# PIC32MZ2051W104132 device description
Architecture: MIPS; Family: PIC32MZW; Series: PIC32MZW
Registers are 32-bit, read-write, no defined reset value unless marked. A register's access mark holds for its fields unless they carry their own. Offsets are from the block's base; [hi:lo] are bit positions; {n}, {i} and the like mark numbered series; 'fields as' and 'values as' point back to an identical list.

## ADCHS
Instances: ADCHS0 0x1f821000 in periph_pb2
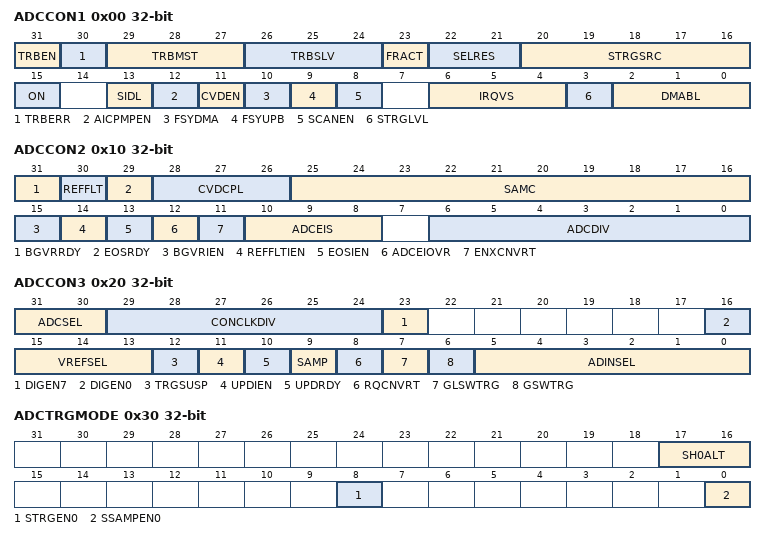
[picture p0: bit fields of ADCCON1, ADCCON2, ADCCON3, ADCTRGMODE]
0x00 ADCCON1 — ADC Control Register 1
  [31] TRBEN — Turbo Channel Enable bit
    1=Enable the Turbo channel; 0=Disable the Turbo channel
  [30] TRBERR — Turbo Channel Error Status bit
    1=An error occurred while setting the Turbo channel and Turbo channel function to be disabled regardless of the TRBEN bit being set to 1; 0=Turbo channel error did not occur
  [29:27] TRBMST — Turbo Master ADCx bits
    {v}=ADC{v} is selected as the Turbo Master (v=0..4)
  [26:24] TRBSLV — Turbo Slave ADCx bits
    {v}=ADC{v} is selected as the Turbo Slave (v=0..4)
  [23] FRACT — Fractional Data Output Format bit
    1=Fractional; 0=Integer
  [22:21] SELRES — Shared ADC Resolution bits
    3=12 bits (default); 2=10 bits; 1=8 bits; 0=6 bits
  [20:16] STRGSRC — Scan Trigger Source Select bits
    31=External Trigger for Validation; {v}=PTG Trigger Out {v-8} (v=20..23); 18=Output Compare 4 period end; 17=Output Compare 3 period end; 16=Output Compare 2 period end; 9=Output Compare 1 period end; 8=General Purpose Timer7; 7=General Purpose Timer5; 6=General Purpose Timer3; 5=General Purpose Timer1; 4=INT0; 2=Software level trigger; 1=Software edge trigger; 0=No Trigger
  [15] ON — ADC Module Enable bit
    1=ADC module is enabled; 0=ADC module is disabled
  [13] SIDL — Stop in Idle Mode bit
    1=Discontinue module operation when device enters Idle mode; 0=Continue module operation in Idle mode
  [12] AICPMPEN — Analog Input Charge Pump Enable bit - see datasheet
    1=Analog input charge pump is enabled (default); 0=Analog input charge pump is disabled
  [11] CVDEN — Capacitive Voltage Division Enable bit
    1=CVD operation is enabled; 0=CVD operation is disabled
  [10] FSYDMA
  [9] FSYUPB
  [8] SCANEN
  [6:4] IRQVS — Interrupt Vector Shift bits
    {v}=Shift x left {v} bit position (v=0..7)
  [3] STRGLVL — Scan Trigger High Level/Positive Edge Sensitivity bit
    1=Scan trigger is high level sensitive. Once STRIG mode is selected (TRGSRCx in the ADCTRGx register); 0=Scan trigger is positive edge sensitive. Once STRIG mode is selected (TRGSRCx in the ADCTRGx register)
  [2:0] DMABL — DMA to System RAM Buffer Length Size bits
    7=Allocates 128 locations in system memory to each analog input; 6=Allocates 64 locations in system memory to each analog input; 5=Allocates 32 locations in system memory to each analog input; 4=Allocates 16 locations in system memory to each analog input; 3=Allocates 8 locations in system memory to each analog input; 2=Allocates 4 locations in system memory to each analog input; 1=Allocates 2 locations in system memory to each analog input; 0=Allocates 1 location in system memory to each analog input
0x10 ADCCON2 — ADC Control Register 2
  [31] BGVRRDY — Band Gap Voltage/ADC Reference Voltage Status bit
    1=Both band gap voltage and ADC reference voltages (Vref) are ready; 0=Either or both band gap voltage and ADC reference voltages (Vref) are not ready
  [30] REFFLT — Band Gap/ Vref / AVdd BOR Fault Status bit
    1=Fault in band gap or the Vref voltage while the ON bit (ADCCON1) was set. Most likely a band gap orVref fault will be caused by a BOR of the analog Vdd supply.; 0=Band gap and Vref voltage are working properly
  [29] EOSRDY — End of Scan Interrupt Status bit
    1=All analog inputs are considered for scanning through the scan trigger (all analog inputs specified in the ADCCSS1 and ADCCSS2 registers) have completed scanning; 0=Scanning has not completed
  [28:26] CVDCPL — Capacitor Voltage Divider Setting bit
    7=7 * 2.5 pF = 17.5 pF; 6=6 * 2.5 pF = 15 pF; 5=5 * 2.5 pF = 12.5 pF; 4=4 * 2.5 pF = 10 pF; 3=3 * 2.5 pF = 7.5 pF; 2=2 * 2.5 pF = 5 pF; 1=1 * 2.5 pF = 2.5 pF; 0=0 * 2.5 pF = 0 pF
  [25:16] SAMC — Sample Time for the Shared ADC bits
    0x3ff=1025 Tad7; 1=3 Tad7; 0=2 Tad7
  [15] BGVRIEN — Band Gap/VREF Voltage Ready Interrupt Enable bit
    1=Interrupt will be generated when the BGVRDDY bit is set; 0=No interrupt is generated when the BGVRRDY bit is set
  [14] REFFLTIEN — Band Gap/VREF Voltage Fault Interrupt Enable bit
    1=Interrupt will be generated when the REFFLT bit is set; 0=No interrupt is generated when the REFFLT bit is set
  [13] EOSIEN — End of Scan Interrupt Enable bit
    1=Interrupt will be generated when EOSRDY bit is set; 0=No interrupt is generated when the EOSRDY bit is set
  [12] ADCEIOVR — Early Interrupt Request Override bit
    1=Early interrupt generation is not overridden and interrupt generation is controlled by the ADCEIEN1 and ADCEIEN2 registers; 0=Early interrupt generation is overridden and interrupt generation is controlled by the ADCGIRQEN1 and ADCGIRQEN2 registers
  [11] ENXCNVRT
  [10:8] ADCEIS — Shared ADC Early Interrupt Select bits
    7=The data ready interrupt is generated 8 ADC clocks prior to end of conversion; 6=The data ready interrupt is generated 7 ADC clocks prior to end of conversion; 1=The data ready interrupt is generated 2 ADC module clocks prior to end of conversion; 0=The data ready interrupt is generated 1 ADC module clock prior to end of conversion
  [6:0] ADCDIV — Shared ADC Clock Divider bits
    127=254 * Tq = Tad7; 3=6 * Tq = Tad7; 2=4 * Tq = Tad7; 1=2 * Tq = Tad7
0x20 ADCCON3 — ADC Control Register 3
  [31:30] ADCSEL — Analog-to-Digital Clock Source bits
    3=System Clock (Tcy); 2=REFCLK3; 1=FRC; 0=PBCLK2
  [29:24] CONCLKDIV — Analog-to-Digital Control Clock Divider bits
    63=64 * Tclk = Tq; 3=4 * Tclk = Tq; 2=3 * Tclk = Tq; 1=2 * Tclk = Tq; 0=Tclk = Tq
  [23] DIGEN7 — Shared ADC Digital Enable bit
    1=ADC7 is digital enabled; 0=ADC7 is digital disabled
  [16] DIGEN0 — ADC0 Digital Enable bit
    1=ADC0 is digital enabled; 0=ADC0 is digital disabled
  [15:13] VREFSEL — Voltage Reference Input Selection bits
    0=External AVDD and AVSS
  [12] TRGSUSP — Trigger Suspend bit
    1=Triggers are blocked from starting a new analog-to-digital conversion; 0=Triggers are not blocked
  [11] UPDIEN — Update Ready Interrupt Enable bit
    1=Interrupt will be generated when the UPDRDY bit is set by hardware; 0=No interrupt is generated
  [10] UPDRDY — ADC Update Ready Status bit
    1=ADC SFRs can be updated; 0=ADC SFRs cannot be updated
  [9] SAMP — Class 2 and Class 3 Analog Input Sampling Enable bit
    1=The ADC S&H amplifier is sampling; 0=The ADC S&H amplifier is holding
  [8] RQCNVRT — Individual ADC Input Conversion Request bit
    1=Trigger the conversion of the selected ADC input as specified by the ADINSEL bits; 0=Do not trigger the conversion
  [7] GLSWTRG — Global Level Software Trigger bit
    1=Trigger conversion for ADC inputs that have selected the GLSWTRG bit as the trigger signal; 0=Do not trigger an analog-to-digital conversion
  [6] GSWTRG — Global Software Trigger bit
    1=Trigger conversion for ADC inputs that have selected the GSWTRG bit as the trigger signal; 0=Do not trigger an analog-to-digital conversion
  [5:0] ADINSEL — Analog Input Select bits
    44=MAX_AN_INPUT + 2 = IVTEMP; 43=MAX_AN_INPUT + 1 = IVREF; 42=MAX_AN_INPUT = AN[MAX_AN_INPUT]; 1=AN1; 0=AN0
0x30 ADCTRGMODE — ADC Triggering Mode for Dedicated ADC Register
  [17:16] SH0ALT — ADC0 Analog Input Select bit
    2=ANB0; 1=ANA0; 0=AN0
  [8] STRGEN0 — ADC0 Presynchronized Triggers bit
    1=ADC0 uses presynchronized triggers; 0=ADC0 does not use presynchronized triggers
  [0] SSAMPEN0 — ADC0 Synchronous Sampling bit
    1=ADC0 uses synchronous sampling for the first sample after being idle or disabled; 0=ADC0 does not use synchronous sampling
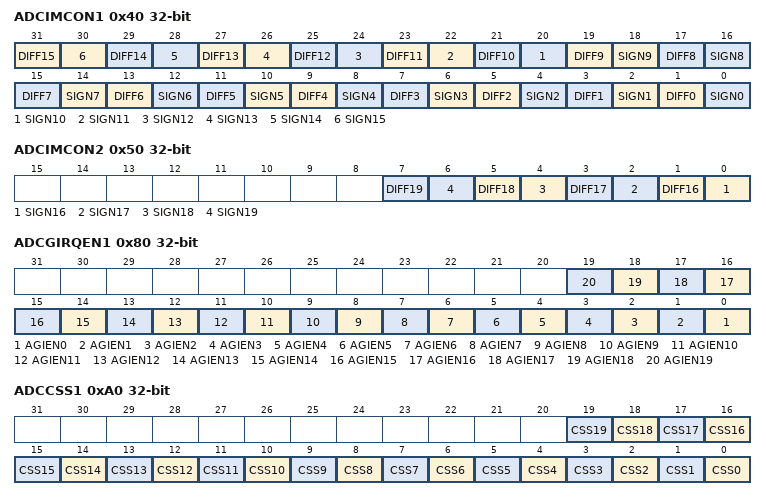
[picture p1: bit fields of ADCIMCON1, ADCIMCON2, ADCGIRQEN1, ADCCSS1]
0x40 ADCIMCON1 — ADC Input Mode Control Register 1
  [2n+1] DIFF{n} (n=9..15) — AN{n} Mode bit
    1=AN{n} is using Differential mode; 0=AN{n} is using Single-ended mode
  [2n] SIGN{n} (n=0..15) — AN{n} Signed Data Mode bit
    1=AN{n} is using Signed Data mode; 0=AN{n} is using Unsigned Data mode
  [17] DIFF8 — AN 8 Mode bit
    1=AN8 is using Differential mode; 0=AN8 is using Single-ended mode
  [2n+1] DIFF{n} (n=0..7) — AN{n} Mode bit
    values as DIFF9
0x50 ADCIMCON2 — ADC Input Mode Control Register 2
  [2n-31] DIFF{n} (n=16..19) — AN{n} Mode bit
    values as ADCIMCON1.DIFF9
  [2n-32] SIGN{n} (n=16..19) — AN{n} Signed Data Mode bit
    values as ADCIMCON1.SIGN0
0x80 ADCGIRQEN1 — ADC Global Interrupt Enable Register 1
  [all] fields
    1=Interrupts are enabled for the selected analog input. The interrupt is generated after the converted data is ready (indicated by the ARDYx bit (x = 31-0) of the ADCDSTAT1 register); 0=Interrupts are disabled
  [n] AGIEN{n} (n=0..19) — ADC Global Interrupt Enable bits for analog input {n}
0xA0 ADCCSS1 — ADC Common Scan Select Register 1
  [all] fields
    1=Select ANx for input scan; 0=Skip ANx for input scan
  [n] CSS{n} (n=0..19) — Analog Common Scan Select bits {n}
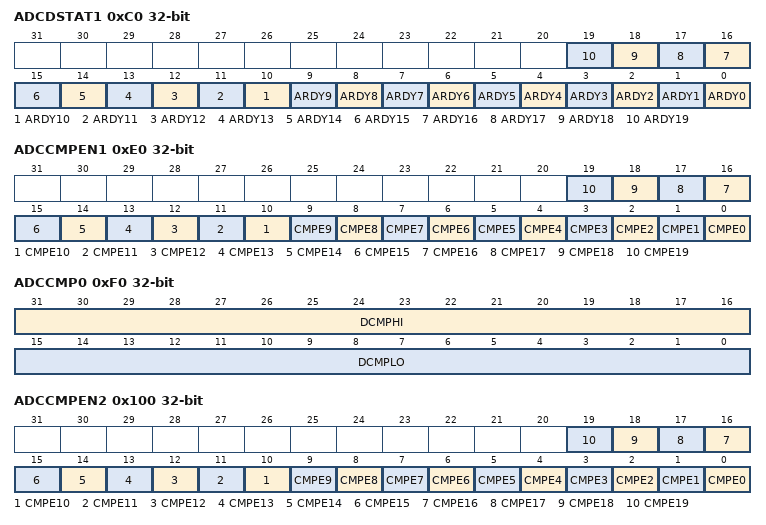
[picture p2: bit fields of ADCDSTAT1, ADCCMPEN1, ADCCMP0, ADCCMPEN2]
0xC0 ADCDSTAT1 — ADC Data Ready Status Register 1
  [all] fields
    1=This bit is set when converted data is ready in the data register; 0=This bit is cleared when the associated data register is read
  [n] ARDY{n} (n=0..19) — Conversion Data Ready for Corresponding Analog Input Ready bit {n}
0xE0 ADCCMPEN1 — ADC Digital Comparator x Enable Register
  [n] CMPE{n} (n=0..19)
0xF0 ADCCMP0 — ADC Digital Comparator x Limit Value Register
  [31:16] DCMPHI, [15:0] DCMPLO
0x100 ADCCMPEN2 — ADC Digital Comparator x Enable Register
  [n] CMPE{n} (n=0..19)
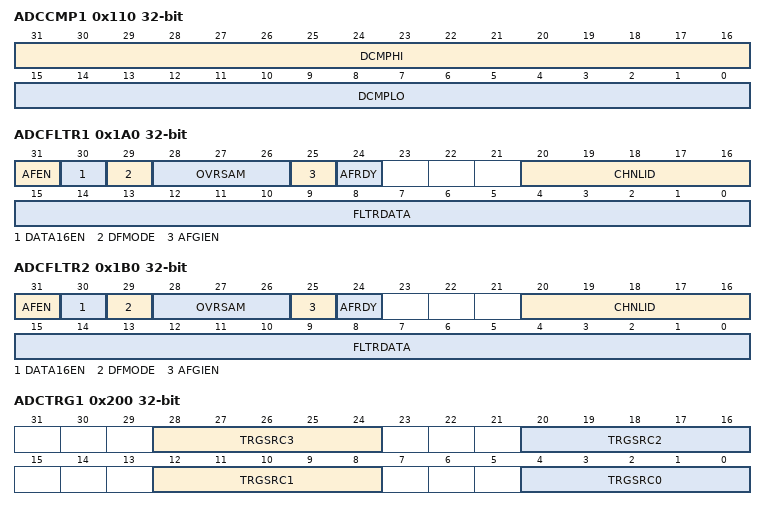
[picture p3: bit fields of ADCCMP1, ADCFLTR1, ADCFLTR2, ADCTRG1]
0x110 ADCCMP1 — ADC Digital Comparator x Limit Value Register
  [31:16] DCMPHI, [15:0] DCMPLO
0x1A0 ADCFLTR1 — ADC Digital Filter x Register
  [31] AFEN — Digital Filter x Enable bit
    1=Digital filter is enabled; 0=Digital filter is disabled and the AFRDY status bit is cleared
  [30] DATA16EN — Filter Significant Data Length bit
    1=All 16 bits of the filter output data are significant; 0=Only the first 12 bits are significant
  [29] DFMODE — ADC Filter Mode bit
    1=Filter x works in Averaging mode; 0=Filter x works in Oversampling Filter mode (default)
  [28:26] OVRSAM — Oversampling Filter Ratio bits
    7=(If DFMODE is 0) 128 samples (shift sum 3 bits to right; 6=(If DFMODE is 0) 32 samples (shift sum 2 bits to right; 5=(If DFMODE is 0) 8 samples (shift sum 1 bit to right; 4=(If DFMODE is 0) 2 samples (shift sum 0 bits to right; 3=(If DFMODE is 0) 256 samples (shift sum 4 bits to right; 2=(If DFMODE is 0) 64 samples (shift sum 3 bits to right; 1=(If DFMODE is 0) 16 samples (shift sum 2 bits to right; 0=(If DFMODE is 0) 4 samples (shift sum 1 bit to right
  [25] AFGIEN — Digital Filter x Interrupt Enable bit
    1=Digital filter interrupt is enabled and is generated by the AFRDY status bit; 0=Digital filter is disabled
  [24] AFRDY — Digital Filter x Data Ready Status bit
    1=Data is ready in the FLTRDATA bits; 0=Data is not ready
  [20:16] CHNLID — Digital Filter Analog Input Selection bits
    11=AN11; 2=AN2; 1=AN1; 0=AN0
  [15:0] FLTRDATA
0x1B0 ADCFLTR2 — ADC Digital Filter x Register
  fields as ADCFLTR1
0x200 ADCTRG1 — ADC Trigger Source 1 Register
  [all] fields
    31=External Trigger for Validation; {v}=PTG Trigger Out {v-8} (v=20..23); 18=Output Compare 4 period end; 17=Output Compare 3 period end; 16=Output Compare 2 period end; 9=Output Compare 1 period end; 8=General Purpose Timer7; 7=General Purpose Timer5; 6=General Purpose Timer3; 5=General Purpose Timer1; 4=INT0; 3=Scan trigger (see Note); 2=Software level trigger; 1=Software edge trigger; 0=No Trigger
  [28:24] TRGSRC3 — Trigger Source for Conversion of Analog Input AN3 Select bits
  [20:16] TRGSRC2 — Trigger Source for Conversion of Analog Input AN2 Select bits
  [12:8] TRGSRC1 — Trigger Source for Conversion of Analog Input AN1 Select bits
  [4:0] TRGSRC0 — Trigger Source for Conversion of ADC0 Module Select bits
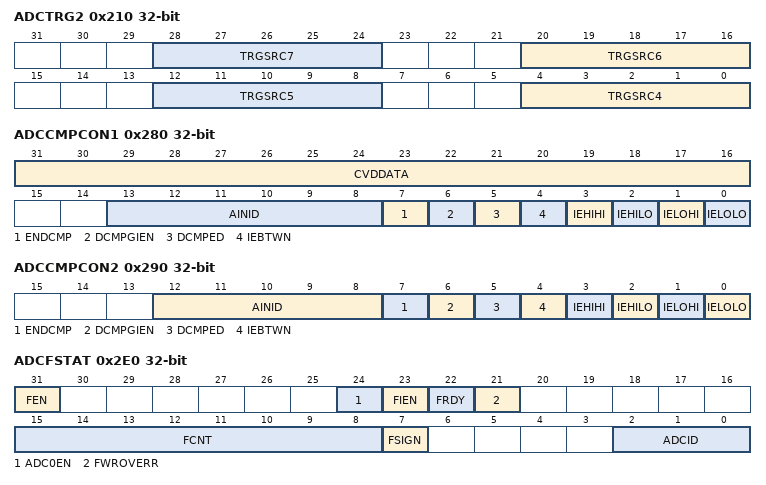
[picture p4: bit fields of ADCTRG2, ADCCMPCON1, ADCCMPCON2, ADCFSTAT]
0x210 ADCTRG2 — ADC Trigger Source 2 Register
  [all] fields
    values as the fields of ADCTRG1
  [8n-28:8n-32] TRGSRC{n} (n=4..7) — Trigger Source for Conversion of Analog Input AN{n} Select bits
0x280 ADCCMPCON1 — ADC Digital Comparator 1 Control Register
  [31:16] CVDDATA, [13:8] AINID, [7] ENDCMP, [6] DCMPGIEN, [5] DCMPED, [4] IEBTWN, [3] IEHIHI, [2] IEHILO, [1] IELOHI, [0] IELOLO
0x290 ADCCMPCON2 — ADC Digital Comparator 2 Control Register
  [12:8] AINID, [7] ENDCMP, [6] DCMPGIEN, [5] DCMPED, [4] IEBTWN, [3] IEHIHI, [2] IEHILO, [1] IELOHI, [0] IELOLO
0x2E0 ADCFSTAT — ADC FIFO Status Register
  [31] FEN — FIFO Enable bit
    1=FIFO is enabled; 0=FIFO is disabled; no data is being saved into the FIFO
  [24] ADC0EN — ADC0 Enable bit
    1=Converted output data of ADC is stored in the FIFO; 0=Converted output data of ADC is not stored in the FIFO
  [23] FIEN — FIFO Interrupt Enable bit
    1=FIFO interrupts are enabled; an interrupt is generated once the FRDY bit is set; 0=FIFO interrupts are disabled
  [22] FRDY — FIFO Data Ready Interrupt Status bit
    1=FIFO has data to be read; 0=No data is available in the FIFO
  [21] FWROVERR — FIFO Write Overflow Error Status bit
    1=A write overflow error in the FIFO has occurred (circular FIFO); 0=A write overflow error in the FIFO has not occurred
  [15:8] FCNT
  [7] FSIGN
  [2:0] ADCID — ADCx Identifier bits
    4=Converted data of ADC4 is stored in FIFO; 0=Converted data of ADC0 is stored in FIFO
0x2F0 ADCFIFO ro — ADC FIFO Data Register
  [31:0] DATA
0x300 ADCBASE
  [15:0] ADCBASE
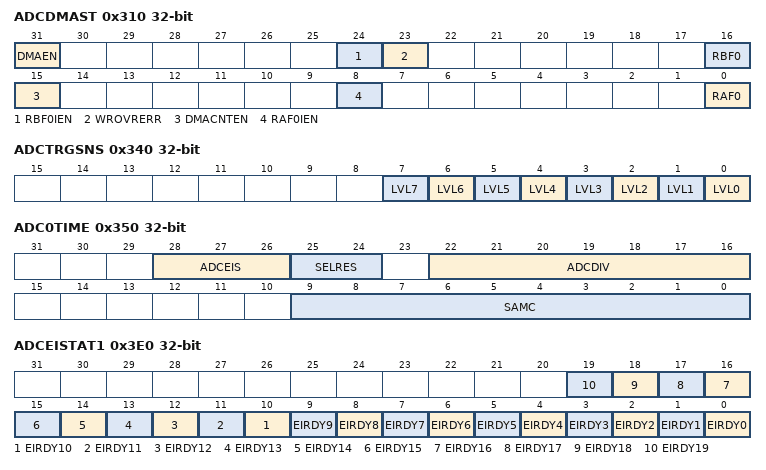
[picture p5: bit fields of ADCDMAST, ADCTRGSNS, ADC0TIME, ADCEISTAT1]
0x310 ADCDMAST
  [31] DMAEN, [24] RBF0IEN, [23] WROVRERR, [16] RBF0, [15] DMACNTEN, [8] RAF0IEN, [0] RAF0
0x320 ADCCNTB
0x330 ADCDMAB
  [31:0] ADDMAB
0x340 ADCTRGSNS — ADC Trigger Level/Edge Sensitivity Register
  [all] fields
    1=Analog input is sensitive to the high level of its trigger (level sensitivity implies retriggering as long as the trigger signal remains high); 0=Analog input is sensitive to the positive edge of its trigger (this is the value after a reset)
  [n] LVL{n} (n=0..7) — Trigger Level and Edge Sensitivity bit {n}
0x350 ADC0TIME — Dedicated ADCx Timing Register 0
  [28:26] ADCEIS — ADCx Early Interrupt Select bits
    7=The data ready interrupt is generated 8 ADC clocks prior to the end of conversion; 6=The data ready interrupt is generated 7 ADC clocks prior to the end of conversion; 1=The data ready interrupt is generated 2 ADC clocks prior to the end of conversion; 0=The data ready interrupt is generated 1 ADC clock prior to the end of conversion
  [25:24] SELRES — ADCx Resolution Select bits
    3=12 bits; 2=10 bits; 1=8 bits; 0=6 bits
  [22:16] ADCDIV — ADCx Clock Divisor bits
    127=254 * Tq = Tadx; 3=6 * Tq = Tadx; 2=4 * Tq = Tadx; 1=2 * Tq = Tadx
  [9:0] SAMC — ADCx Sample Time bits
    0x3ff=1025 Tadx; 1=3 Tadx; 0=2 Tadx
0x3E0 ADCEISTAT1
  [all] fields
    1=This bit is set when the early interrupt event occurs for the specified analog input. An interrupt will be generated if early interrupts are enabled in the ADCEIEN1 register. For the Class 1 analog inputs; 0=Interrupts are disabled
  [n] EIRDY{n} (n=0..19) — Early Interrupt for Corresponding Analog Input Ready bit {n}
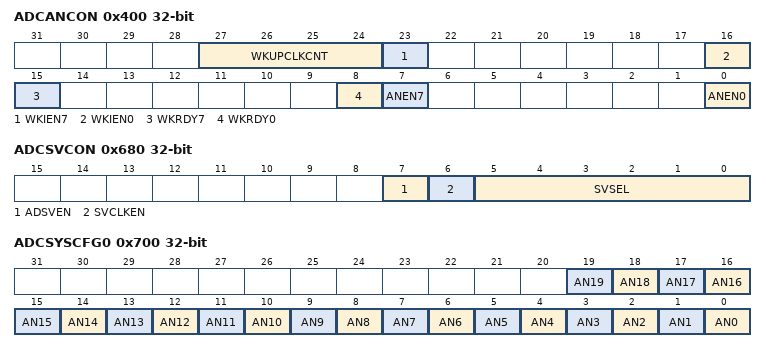
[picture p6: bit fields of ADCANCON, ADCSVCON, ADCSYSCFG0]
0x400 ADCANCON — ADC Analog Warm-up Control Register
  [27:24] WKUPCLKCNT — Wake-up Clock Count bits
    15=32; 6=64 clocks; 5=32 clocks; {v}=16 clocks (v=0..4)
  [23] WKIEN7 — Shared ADC Wake-up Interrupt Enable bit
    1=Enable interrupt and generate interrupt when the WKRDY7 status bit is set; 0=Disable interrupt
  [16] WKIEN0 — ADC 0 Wake-up Interrupt Enable bit
    1=Enable interrupt and generate interrupt when the WKRDYx status bit is set; 0=Disable interrupt
  [15] WKRDY7 — Shared ADC Wake-up Status bit
    1=ADC7 Analog and Bias circuitry ready after the wake-up count number 2WKUPEXP clocks after setting ANEN7 to 1; 0=ADC7 Analog and Bias circuitry is not ready
  [8] WKRDY0 — ADC 0 Wake-up Status bit
    1=ADCx Analog and Bias circuitry ready after the wake-up count number 2WKUPEXP clocks after setting ANENx to 1; 0=ADCx Analog and Bias circuitry is not ready
  [7] ANEN7 — Shared ADC Analog and Bias Circuitry Enable bit
    1=Analog and bias circuitry enabled. Once the analog and bias circuit is enabled; 0=Analog and bias circuitry disabled
  [0] ANEN0 — ADC0 Analog and Bias Circuitry Enable bit
    values as ANEN7
0x600 ADC0CFG
  [31:0] ADCCFG
0x670 ADC7CFG
  [31:0] ADCCFG
0x680 ADCSVCON
  [7] ADSVEN, [6] SVCLKEN, [5:0] SVSEL
0x700 ADCSYSCFG0
  [n] AN{n} (n=0..19)
{0xA00+0x10*i} ADCDATA{i} (i=0..23)
  [31:0] DATA

## Notices in the file
Copyright (c) 2019 Microchip Technology Inc.
SPDX-License-Identifier: Apache-2.0
Licensed under the Apache License, Version 2.0 (the "License");
you may not use this file except in compliance with the License.
You may obtain a copy of the License at
http://www.apache.org/licenses/LICENSE-2.0
Unless required by applicable law or agreed to in writing, software
distributed under the License is distributed on an "AS IS" BASIS,
WITHOUT WARRANTIES OR CONDITIONS OF ANY KIND, either express or implied.
See the License for the specific language governing permissions and
limitations under the License.
